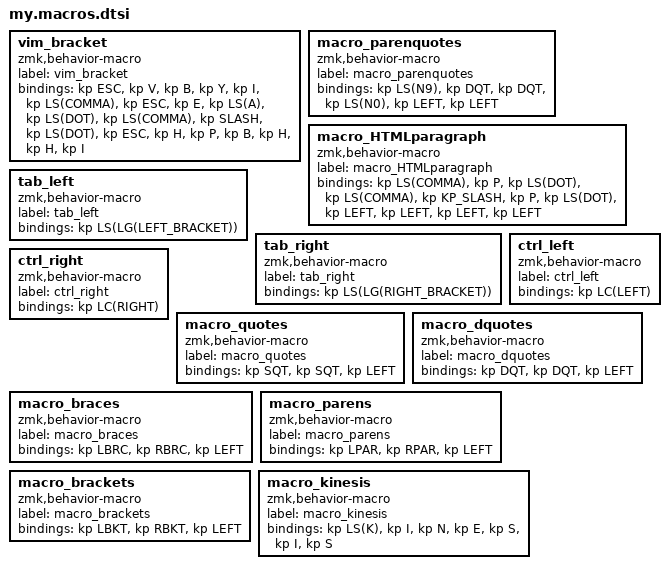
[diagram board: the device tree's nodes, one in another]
vim_bracket: vim_bracket{
compatible = "zmk,behavior-macro";
label = "vim_bracket";
#binding-cells = <0>;
bindings = <&kp ESC>, <&kp V>, <&kp B>, <&kp Y>, <&kp I>, <&kp LS(COMMA)>, <&kp ESC>, <&kp E>, <&kp LS(A)>, <&kp LS(DOT)>, <&kp LS(COMMA)>, <&kp SLASH>, <&kp LS(DOT)>, <&kp ESC>, <&kp H>, <&kp P>, <&kp B>, <&kp H>, <&kp H>, <&kp I>;
}; 
macro_parenquotes: macro_parenquotes{
compatible = "zmk,behavior-macro";
label = "macro_parenquotes";
#binding-cells = <0>;
bindings = <&kp LS(N9)>, <&kp DQT>, <&kp DQT>, <&kp LS(N0)>, <&kp LEFT>, <&kp LEFT>;
}; 
macro_HTMLparagraph: macro_HTMLparagraph{
compatible = "zmk,behavior-macro";
label = "macro_HTMLparagraph";
#binding-cells = <0>;
bindings = <&kp LS(COMMA)>, <&kp P>, <&kp LS(DOT)>, <&kp LS(COMMA)>, <&kp KP_SLASH>, <&kp P>, <&kp LS(DOT)>, <&kp LEFT>, <&kp LEFT>, <&kp LEFT>, <&kp LEFT>;
}; 
tab_left: tab_left{
compatible = "zmk,behavior-macro";
label = "tab_left";
#binding-cells = <0>;
bindings = <&kp LS(LG(LEFT_BRACKET))>;
};
tab_right: tab_right{
compatible = "zmk,behavior-macro";
label = "tab_right";
#binding-cells = <0>;
bindings = <&kp LS(LG(RIGHT_BRACKET))>;
};
ctrl_left: ctrl_left{
compatible = "zmk,behavior-macro";
label = "ctrl_left";
#binding-cells = <0>;
bindings = <&kp LC(LEFT)>;
};
ctrl_right: ctrl_right{
compatible = "zmk,behavior-macro";
label = "ctrl_right";
#binding-cells = <0>;
bindings = <&kp LC(RIGHT)>;
};
macro_quotes: macro_quotes{
compatible = "zmk,behavior-macro";
label = "macro_quotes";
#binding-cells = <0>;
bindings = <&kp SQT>, <&kp SQT>, <&kp LEFT>;
};
macro_dquotes: macro_dquotes{
compatible = "zmk,behavior-macro";
label = "macro_dquotes";
#binding-cells = <0>;
bindings = <&kp DQT>, <&kp DQT>, <&kp LEFT>;
};
macro_braces: macro_braces{
compatible = "zmk,behavior-macro";
label = "macro_braces";
#binding-cells = <0>;
bindings = <&kp LBRC>, <&kp RBRC>, <&kp LEFT>;
};
macro_parens: macro_parens{
compatible = "zmk,behavior-macro";
label = "macro_parens";
#binding-cells = <0>;
bindings = <&kp LPAR>, <&kp RPAR>, <&kp LEFT>;
};
macro_brackets: macro_brackets{
compatible = "zmk,behavior-macro";
label = "macro_brackets";
#binding-cells = <0>;
bindings = <&kp LBKT>, <&kp RBKT>, <&kp LEFT>;
};
macro_kinesis: macro_kinesis{
compatible = "zmk,behavior-macro";
label = "macro_kinesis";
#binding-cells = <0>;
bindings = <&kp LS(K)>, <&kp I>, <&kp N>, <&kp E>, <&kp S>, <&kp I>, <&kp S>;
};
